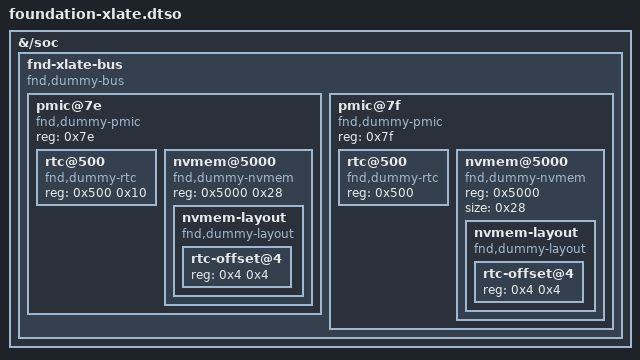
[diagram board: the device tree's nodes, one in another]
// SPDX-License-Identifier: GPL-2.0
/*
 * Live repro for "OF: Bad cell count for .../pmic@74" without touching the PMIC.
 * A fake non-MMIO bus (#size-cells = <0>, like i2c0) holds two PMIC-shaped
 * subtrees: pmic@7e is the old layout (#size-cells = <1>), pmic@7f the fixed
 * one (#size-cells = <0>). Nothing binds "fnd,*"; fnd_xlate_v1.ko populates
 * the children the way simple-mfd-i2c and the nvmem layout code do.
 */
/dts-v1/;
/plugin/;

/ {
	fragment@0 {
		target-path = "/soc";
		__overlay__ {
			fnd-xlate-bus {
				compatible = "fnd,dummy-bus";
				#address-cells = <1>;
				#size-cells = <0>;

				pmic@7e {
					compatible = "fnd,dummy-pmic";
					reg = <0x7e>;
					#address-cells = <1>;
					#size-cells = <1>;

					rtc@500 {
						compatible = "fnd,dummy-rtc";
						reg = <0x500 0x10>;
					};

					nvmem@5000 {
						compatible = "fnd,dummy-nvmem";
						reg = <0x5000 0x28>;

						nvmem-layout {
							compatible = "fnd,dummy-layout";
							#address-cells = <1>;
							#size-cells = <1>;

							rtc-offset@4 {
								reg = <0x4 0x4>;
							};
						};
					};
				};

				pmic@7f {
					compatible = "fnd,dummy-pmic";
					reg = <0x7f>;
					#address-cells = <1>;
					#size-cells = <0>;

					rtc@500 {
						compatible = "fnd,dummy-rtc";
						reg = <0x500>;
					};

					nvmem@5000 {
						compatible = "fnd,dummy-nvmem";
						reg = <0x5000>;
						size = <0x28>;

						nvmem-layout {
							compatible = "fnd,dummy-layout";
							#address-cells = <1>;
							#size-cells = <1>;

							rtc-offset@4 {
								reg = <0x4 0x4>;
							};
						};
					};
				};
			};
		};
	};
};
